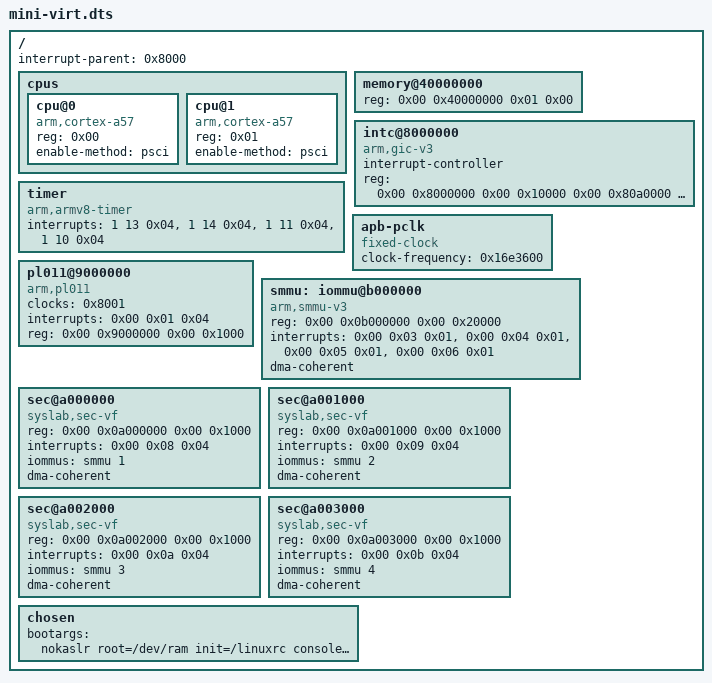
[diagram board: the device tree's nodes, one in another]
/dts-v1/;

/ {
    #size-cells = <0x02>;
    #address-cells = <0x02>;
    interrupt-parent = <0x8000>;

    cpus {
        #size-cells = <0x00>;
        #address-cells = <0x01>;
        cpu@0 {
            reg = <0x00>;
			enable-method = "psci";
            compatible = "arm,cortex-a57";
        };
        cpu@1 {
            reg = <0x01>;
			enable-method = "psci"; // this is for secondary cpu power on
            compatible = "arm,cortex-a57";
        };
    };

    memory@40000000 { reg = <0x00 0x40000000 0x01 0x00>; };

    intc@8000000 {
        phandle = <0x8000>;
        interrupt-controller;
        #interrupt-cells = <0x03>;
        reg = <0x00 0x8000000 0x00 0x10000 0x00 0x80a0000 0x00 0xf60000>;
        compatible = "arm,gic-v3";
    };

    timer {
        // https://www.kernel.org/doc/Documentation/devicetree/bindings/interrupt-controller/arm%2Cgic.yaml
        // https://www.kernel.org/doc/Documentation/devicetree/bindings/arm/arch_timer.txt
        interrupts = <1 13 0x04>, // secure
                     <1 14 0x04>, // non-secure
                     <1 11 0x04>, // virtual
                     <1 10 0x04>; // hypervisor
        compatible = "arm,armv8-timer";
    };

    apb-pclk {
        phandle = <0x8001>;
        clock-frequency = <0x16e3600>;
        #clock-cells = <0x00>;
        compatible = "fixed-clock";
    };

    pl011@9000000 {
        clock-names = "apb_pclk";
        clocks = <0x8001>;
        interrupts = <0x00 0x01 0x04>;
        reg = <0x00 0x9000000 0x00 0x1000>;
        compatible = "arm,pl011", "arm,primecell";
    };

	smmu: iommu@b000000 {
		compatible = "arm,smmu-v3";
		reg = <0x00 0x0b000000 0x00 0x20000>;
		interrupts = <0x00 0x03 0x01>,
			     <0x00 0x04 0x01>,
			     <0x00 0x05 0x01>,
			     <0x00 0x06 0x01>;
		interrupt-names = "eventq", "priq", "cmdq-sync", "gerror";
		#iommu-cells = <0x01>;
		dma-coherent;
	};

	sec@a000000 {
		compatible = "syslab,sec-vf";
		reg = <0x00 0x0a000000 0x00 0x1000>;
		// VF 0: SPI 8, GIC INTID 40, level-high.
		interrupts = <0x00 0x08 0x04>;
		iommus = <&smmu 1>;
		dma-coherent;
	};

	sec@a001000 {
		compatible = "syslab,sec-vf";
		reg = <0x00 0x0a001000 0x00 0x1000>;
		// VF 1: SPI 9, GIC INTID 41, level-high.
		interrupts = <0x00 0x09 0x04>;
		iommus = <&smmu 2>;
		dma-coherent;
	};

	sec@a002000 {
		compatible = "syslab,sec-vf";
		reg = <0x00 0x0a002000 0x00 0x1000>;
		// VF 2: SPI 10, GIC INTID 42, level-high.
		interrupts = <0x00 0x0a 0x04>;
		iommus = <&smmu 3>;
		dma-coherent;
	};

	sec@a003000 {
		compatible = "syslab,sec-vf";
		reg = <0x00 0x0a003000 0x00 0x1000>;
		// VF 3: SPI 11, GIC INTID 43, level-high.
		interrupts = <0x00 0x0b 0x04>;
		iommus = <&smmu 4>;
		dma-coherent;
	};


    chosen { bootargs = "nokaslr root=/dev/ram init=/linuxrc console=ttyAMA0 console=ttyS0"; };
};
